# S6E1A1 register map
File version: 1.1
Registers are 8-bit, read-write, reset 0x0 unless marked. A register's access mark holds for its fields unless they carry their own. Offsets are from the block's base; [hi:lo] are bit positions; {n}, {i} and the like mark numbered series.

## FASTIO — FASTIO Registers
Base 0xF8000000
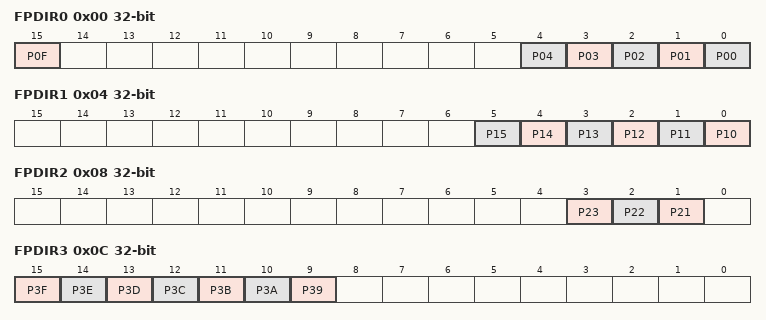
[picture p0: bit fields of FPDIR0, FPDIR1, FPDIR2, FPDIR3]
0x00 FPDIR0 32-bit ro — Fast GPIO Input Data Register 0
  [15] P0F — Bit15 of FPDIR0
  [n] P{n:02} (n=0..4) — Bit{n} of FPDIR0
0x04 FPDIR1 32-bit ro — Fast GPIO Input Data Register 1
  [n-10] P{n} (n=10..15) — Bit{n-10} of FPDIR1
0x08 FPDIR2 32-bit ro — Fast GPIO Input Data Register 2
  [3] P23 — Bit3 of FPDIR2
  [2] P22 — Bit2 of FPDIR2
  [1] P21 — Bit1 of FPDIR2
0x0C FPDIR3 32-bit ro — Fast GPIO Input Data Register 3
  [15] P3F — Bit15 of FPDIR3
  [14] P3E — Bit14 of FPDIR3
  [13] P3D — Bit13 of FPDIR3
  [12] P3C — Bit12 of FPDIR3
  [11] P3B — Bit11 of FPDIR3
  [10] P3A — Bit10 of FPDIR3
  [9] P39 — Bit9 of FPDIR3
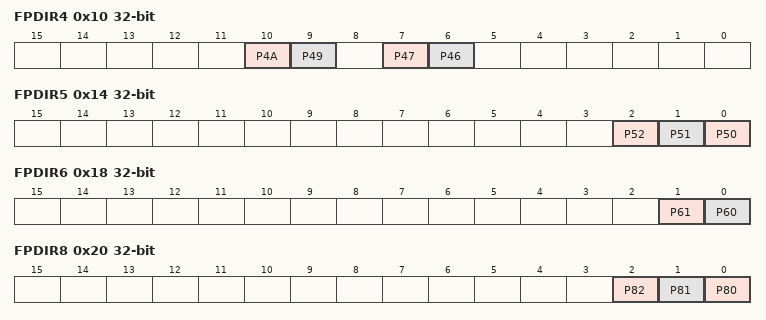
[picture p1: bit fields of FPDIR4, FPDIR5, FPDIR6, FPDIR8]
0x10 FPDIR4 32-bit ro — Fast GPIO Input Data Register 4
  [10] P4A — Bit10 of FPDIR4
  [9] P49 — Bit9 of FPDIR4
  [7] P47 — Bit7 of FPDIR4
  [6] P46 — Bit6 of FPDIR4
0x14 FPDIR5 32-bit ro — Fast GPIO Input Data Register 5
  [2] P52 — Bit2 of FPDIR5
  [1] P51 — Bit1 of FPDIR5
  [0] P50 — Bit0 of FPDIR5
0x18 FPDIR6 32-bit ro — Fast GPIO Input Data Register 6
  [1] P61 — Bit1 of FPDIR6
  [0] P60 — Bit0 of FPDIR6
0x20 FPDIR8 32-bit ro — Fast GPIO Input Data Register 8
  [2] P82 — Bit2 of FPDIR8
  [1] P81 — Bit1 of FPDIR8
  [0] P80 — Bit0 of FPDIR8
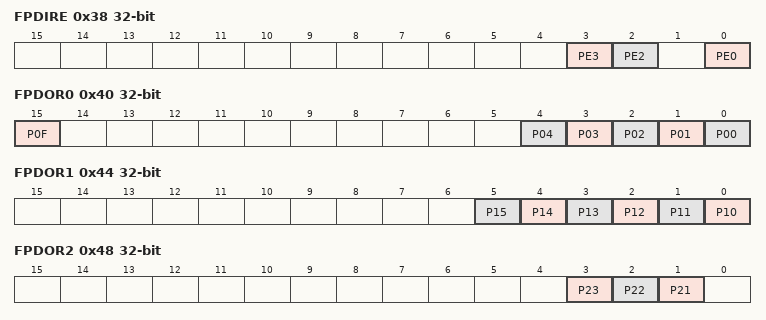
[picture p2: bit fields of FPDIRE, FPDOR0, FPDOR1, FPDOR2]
0x38 FPDIRE 32-bit ro — Fast GPIO Input Data Register E
  [3] PE3 — Bit3 of FPDIRE
  [2] PE2 — Bit2 of FPDIRE
  [0] PE0 — Bit0 of FPDIRE
0x40 FPDOR0 32-bit — Fast GPIO Output Data Register 0
  [15] P0F — Bit15 of FPDOR0
  [n] P{n:02} (n=0..4) — Bit{n} of FPDOR0
0x44 FPDOR1 32-bit — Fast GPIO Output Data Register 1
  [n-10] P{n} (n=10..15) — Bit{n-10} of FPDOR1
0x48 FPDOR2 32-bit — Fast GPIO Output Data Register 2
  [3] P23 — Bit3 of FPDOR2
  [2] P22 — Bit2 of FPDOR2
  [1] P21 — Bit1 of FPDOR2
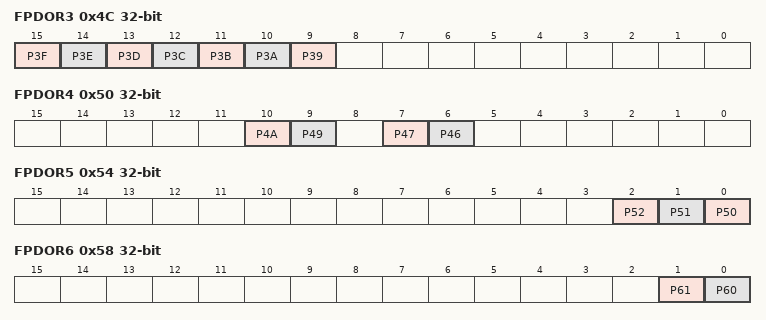
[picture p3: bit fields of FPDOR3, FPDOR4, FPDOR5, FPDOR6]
0x4C FPDOR3 32-bit — Fast GPIO Output Data Register 3
  [15] P3F — Bit15 of FPDOR3
  [14] P3E — Bit14 of FPDOR3
  [13] P3D — Bit13 of FPDOR3
  [12] P3C — Bit12 of FPDOR3
  [11] P3B — Bit11 of FPDOR3
  [10] P3A — Bit10 of FPDOR3
  [9] P39 — Bit9 of FPDOR3
0x50 FPDOR4 32-bit — Fast GPIO Output Data Register 4
  [10] P4A — Bit10 of FPDOR4
  [9] P49 — Bit9 of FPDOR4
  [7] P47 — Bit7 of FPDOR4
  [6] P46 — Bit6 of FPDOR4
0x54 FPDOR5 32-bit — Fast GPIO Output Data Register 5
  [2] P52 — Bit2 of FPDOR5
  [1] P51 — Bit1 of FPDOR5
  [0] P50 — Bit0 of FPDOR5
0x58 FPDOR6 32-bit — Fast GPIO Output Data Register 6
  [1] P61 — Bit1 of FPDOR6
  [0] P60 — Bit0 of FPDOR6
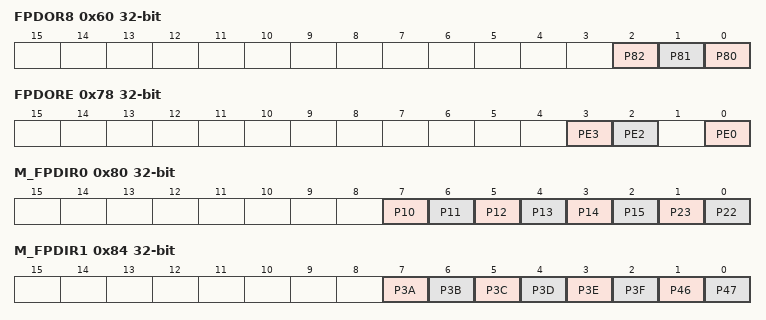
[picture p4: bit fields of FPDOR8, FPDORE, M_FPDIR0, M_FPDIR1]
0x60 FPDOR8 32-bit — Fast GPIO Output Data Register 8
  [2] P82 — Bit2 of FPDOR8
  [1] P81 — Bit1 of FPDOR8
  [0] P80 — Bit0 of FPDOR8
0x78 FPDORE 32-bit — Fast GPIO Output Data Register E
  [3] PE3 — Bit3 of FPDORE
  [2] PE2 — Bit2 of FPDORE
  [0] PE0 — Bit0 of FPDORE
0x80 M_FPDIR0 32-bit ro — Mirror Fast GPIO Input Data Register 0
  [7] P10 — Bit7 of M_FPDIR0
  [6] P11 — Bit6 of M_FPDIR0
  [5] P12 — Bit5 of M_FPDIR0
  [4] P13 — Bit4 of M_FPDIR0
  [3] P14 — Bit3 of M_FPDIR0
  [2] P15 — Bit2 of M_FPDIR0
  [1] P23 — Bit1 of M_FPDIR0
  [0] P22 — Bit0 of M_FPDIR0
0x84 M_FPDIR1 32-bit ro — Mirror Fast GPIO Input Data Register 1
  [7] P3A — Bit7 of M_FPDIR1
  [6] P3B — Bit6 of M_FPDIR1
  [5] P3C — Bit5 of M_FPDIR1
  [4] P3D — Bit4 of M_FPDIR1
  [3] P3E — Bit3 of M_FPDIR1
  [2] P3F — Bit2 of M_FPDIR1
  [1] P46 — Bit1 of M_FPDIR1
  [0] P47 — Bit0 of M_FPDIR1
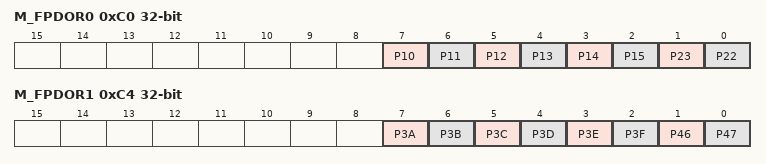
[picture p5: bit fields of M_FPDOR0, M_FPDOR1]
0xC0 M_FPDOR0 32-bit — 32
  [7] P10 — Bit7 of M_FPDOR0
  [6] P11 — Bit6 of M_FPDOR0
  [5] P12 — Bit5 of M_FPDOR0
  [4] P13 — Bit4 of M_FPDOR0
  [3] P14 — Bit3 of M_FPDOR0
  [2] P15 — Bit2 of M_FPDOR0
  [1] P23 — Bit1 of M_FPDOR0
  [0] P22 — Bit0 of M_FPDOR0
0xC4 M_FPDOR1 32-bit — Mirror of Fast GPIO Output Data Register 1
  [7] P3A — Bit7 of M_FPDOR1
  [6] P3B — Bit6 of M_FPDOR1
  [5] P3C — Bit5 of M_FPDOR1
  [4] P3D — Bit4 of M_FPDOR1
  [3] P3E — Bit3 of M_FPDOR1
  [2] P3F — Bit2 of M_FPDOR1
  [1] P46 — Bit1 of M_FPDOR1
  [0] P47 — Bit0 of M_FPDOR1
